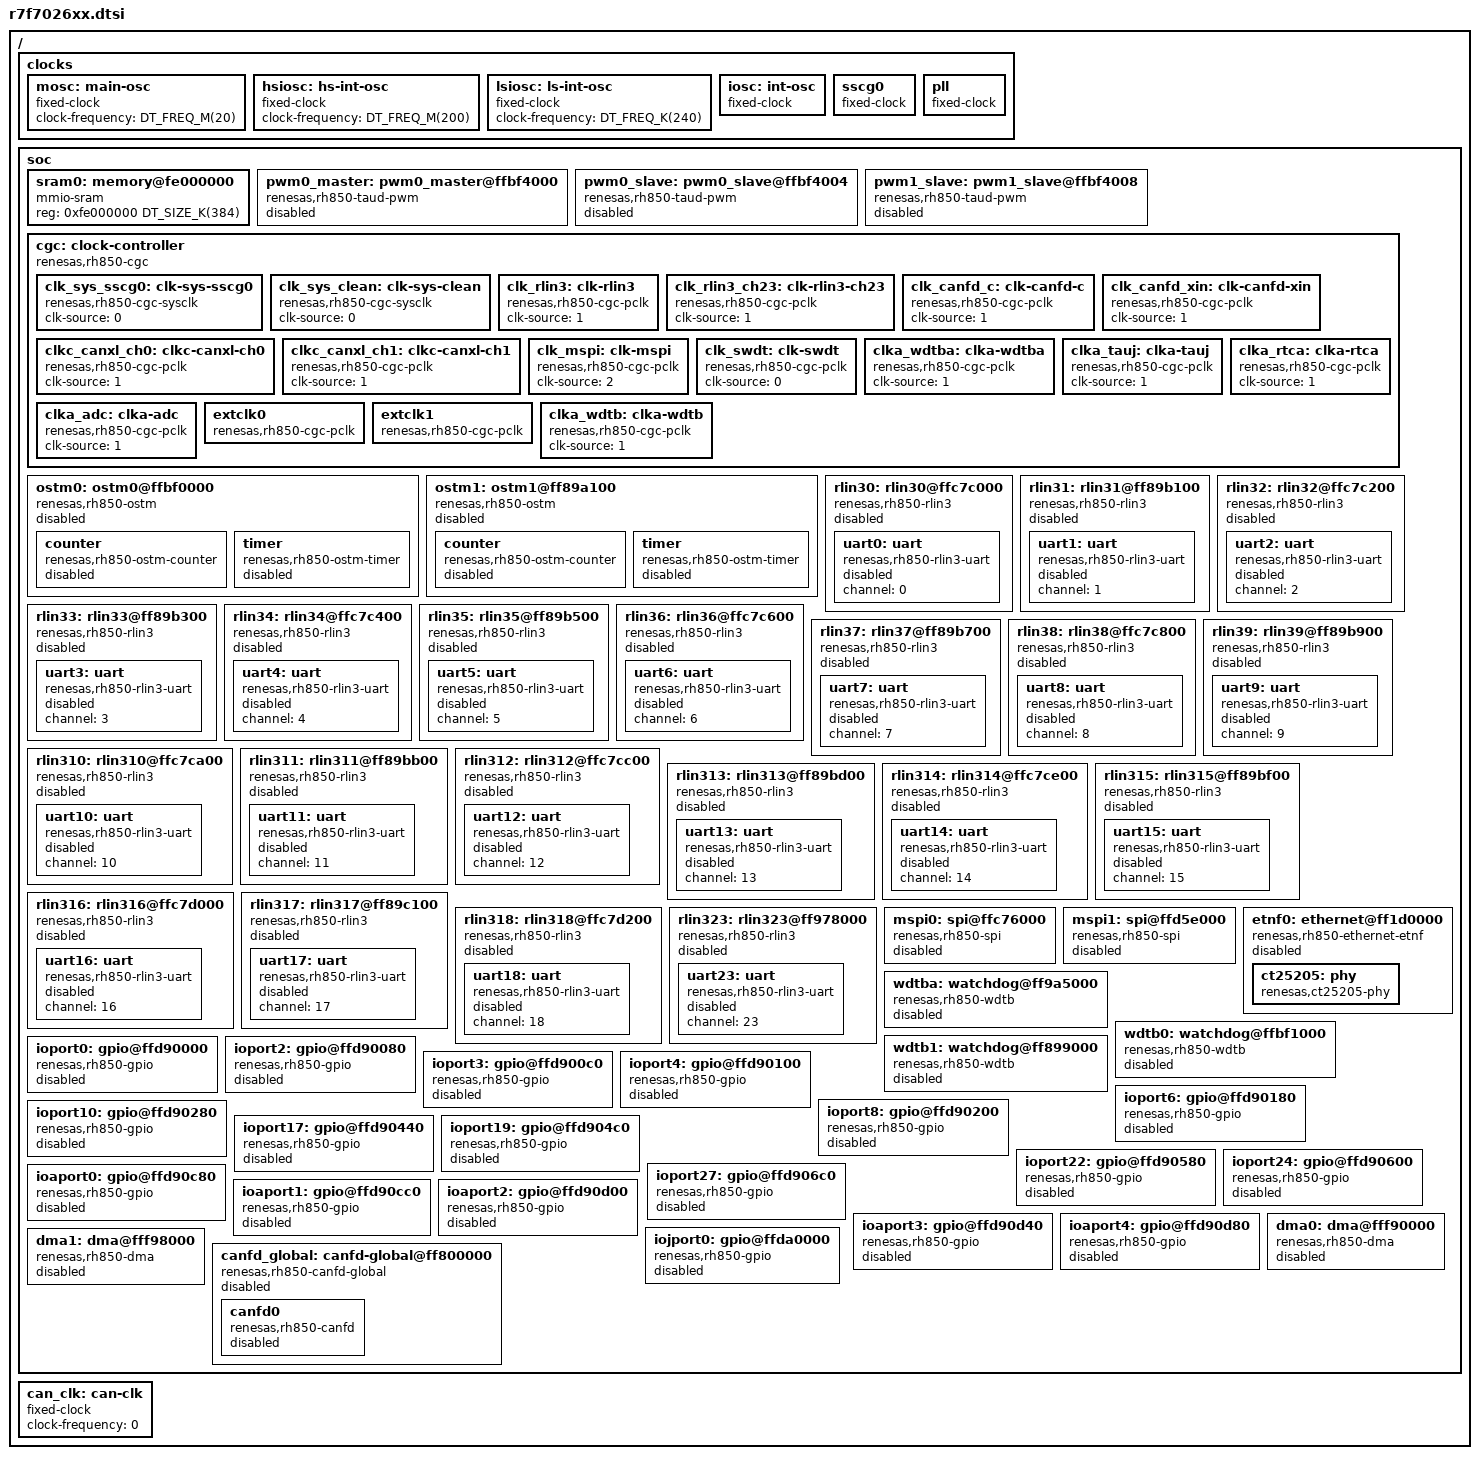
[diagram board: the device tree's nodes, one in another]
/*
 * Copyright (c) 2026 Renesas Electronics Corporation
 *
 * SPDX-License-Identifier: Apache-2.0
 */

#include <rh850/renesas/rh850u2c/u2c-g4kh-common.dtsi>
#include <zephyr/dt-bindings/clock/renesas_rh850u2c_clock.h>
#include <zephyr/dt-bindings/gpio/gpio.h>
#include <freq.h>

/ {
	clocks {
		mosc: main-osc {
			compatible = "fixed-clock";
			clock-frequency = <DT_FREQ_M(20)>;
			#clock-cells = <0>;
			status = "okay";
		};

		hsiosc: hs-int-osc {
			compatible = "fixed-clock";
			clock-frequency = <DT_FREQ_M(200)>;
			#clock-cells = <0>;
			status = "okay";
		};

		lsiosc: ls-int-osc {
			compatible = "fixed-clock";
			clock-frequency = <DT_FREQ_K(240)>;
			#clock-cells = <0>;
			status = "okay";
		};

		iosc: int-osc {
			compatible = "fixed-clock";
			clock-frequency = <DT_FREQ_M(200)>;
			clocks = <&hsiosc>;
			#clock-cells = <0>;
			status = "okay";
		};

		sscg0: sscg0 {
			compatible = "fixed-clock";
			clock-frequency = <DT_FREQ_M(800)>;
			clocks = <&mosc>;
			#clock-cells = <0>;
			status = "okay";
		};

		pll: pll {
			compatible = "fixed-clock";
			clock-frequency = <DT_FREQ_M(800)>;
			clocks = <&mosc>;
			#clock-cells = <0>;
			status = "okay";
		};
	};

	soc {
		sram0: memory@fe000000 {
			compatible = "mmio-sram";
			reg = <0xfe000000 DT_SIZE_K(384)>;
		};

		pwm0_master: pwm0_master@ffbf4000 {
			compatible = "renesas,rh850-taud-pwm";
			reg = <0xffbf4000 0x2000>;
			unit = <0>;
			channel = <0>;
			channel-type = "master";
			interrupts = <10 1>;
			interrupt-parent = <&intc2>;
			status = "disabled";
		};

		pwm0_slave: pwm0_slave@ffbf4004 {
			compatible = "renesas,rh850-taud-pwm";
			reg = <0xffbf4004 0x2000>;
			unit = <0>;
			channel = <1>;
			channel-type = "slave";
			master = <&pwm0_master>;
			interrupts = <149 1>;
			interrupt-parent = <&intc2>;
			#pwm-cells = <3>;
			status = "disabled";
		};

		pwm1_slave: pwm1_slave@ffbf4008 {
			compatible = "renesas,rh850-taud-pwm";
			reg = <0xffbf4008 0x2000>;
			unit = <0>;
			channel = <2>;
			channel-type = "slave";
			master = <&pwm0_master>;
			interrupts = <11 1>;
			interrupt-parent = <&intc2>;
			#pwm-cells = <3>;
			status = "disabled";
		};

		cgc: clock-controller {
			compatible = "renesas,rh850-cgc";
			#clock-cells = <1>;
			status = "okay";

			clk_sys_sscg0: clk-sys-sscg0 {
				compatible = "renesas,rh850-cgc-sysclk";
				clk-source = <0>;
				#clock-cells = <0>;
				status = "okay";
			};

			clk_sys_clean: clk-sys-clean {
				compatible = "renesas,rh850-cgc-sysclk";
				clk-source = <0>;
				#clock-cells = <0>;
				status = "okay";
			};

			clk_rlin3: clk-rlin3 {
				compatible = "renesas,rh850-cgc-pclk";
				clk-source = <1>;
				#clock-cells = <0>;
				status = "okay";
			};

			clk_rlin3_ch23: clk-rlin3-ch23 {
				compatible = "renesas,rh850-cgc-pclk";
				clk-source = <1>;
				#clock-cells = <0>;
				status = "okay";
			};

			clk_canfd_c: clk-canfd-c {
				compatible = "renesas,rh850-cgc-pclk";
				clk-source = <1>;
				#clock-cells = <0>;
				status = "okay";
			};

			clk_canfd_xin: clk-canfd-xin {
				compatible = "renesas,rh850-cgc-pclk";
				clk-source = <1>;
				#clock-cells = <0>;
				status = "okay";
			};

			clkc_canxl_ch0: clkc-canxl-ch0 {
				compatible = "renesas,rh850-cgc-pclk";
				clk-source = <1>;
				#clock-cells = <0>;
				status = "okay";
			};

			clkc_canxl_ch1: clkc-canxl-ch1 {
				compatible = "renesas,rh850-cgc-pclk";
				clk-source = <1>;
				#clock-cells = <0>;
				status = "okay";
			};

			clk_mspi: clk-mspi {
				compatible = "renesas,rh850-cgc-pclk";
				clk-source = <2>;
				#clock-cells = <0>;
				status = "okay";
			};

			clk_swdt: clk-swdt {
				compatible = "renesas,rh850-cgc-pclk";
				clk-source = <0>;
				#clock-cells = <0>;
				status = "okay";
			};

			clka_wdtba: clka-wdtba {
				compatible = "renesas,rh850-cgc-pclk";
				clk-source = <1>;
				#clock-cells = <0>;
				status = "okay";
			};

			clka_tauj: clka-tauj {
				compatible = "renesas,rh850-cgc-pclk";
				clk-source = <1>;
				#clock-cells = <0>;
				status = "okay";
			};

			clka_rtca: clka-rtca {
				compatible = "renesas,rh850-cgc-pclk";
				clk-source = <1>;
				#clock-cells = <0>;
				status = "okay";
			};

			clka_adc: clka-adc {
				compatible = "renesas,rh850-cgc-pclk";
				clk-source = <1>;
				#clock-cells = <0>;
				status = "okay";
			};

			extclk0: extclk0 {
				compatible = "renesas,rh850-cgc-pclk";
				clk-source = <4>;
				div = <0>;
				#clock-cells = <0>;
				status = "okay";
			};

			extclk1: extclk1 {
				compatible = "renesas,rh850-cgc-pclk";
				clk-source = <4>;
				div = <0>;
				#clock-cells = <0>;
				status = "okay";
			};

			clka_wdtb: clka-wdtb {
				compatible = "renesas,rh850-cgc-pclk";
				clk-source = <1>;
				#clock-cells = <0>;
				status = "okay";
			};
		};

		ostm0: ostm0@ffbf0000 {
			compatible = "renesas,rh850-ostm";
			reg = <0xffbf0000 0x20>;
			channel = <0>;
			interrupts = <63 1>;
			interrupt-names = "overflow";
			interrupt-parent = <&intc2>;
			clocks = <&cgc RH850_PCLK(OSTM, 0, PCLK)>;
			status = "disabled";

			counter {
				compatible = "renesas,rh850-ostm-counter";
				status = "disabled";
			};

			timer {
				compatible = "renesas,rh850-ostm-timer";
				status = "disabled";
			};
		};

		ostm1: ostm1@ff89a100 {
			compatible = "renesas,rh850-ostm";
			reg = <0xff89a100 0x20>;
			channel = <1>;
			interrupts = <484 1>;
			interrupt-names = "overflow";
			interrupt-parent = <&intc2>;
			clocks = <&cgc RH850_PCLK(OSTM, 1, PCLK)>;
			status = "disabled";

			counter {
				compatible = "renesas,rh850-ostm-counter";
				status = "disabled";
			};

			timer {
				compatible = "renesas,rh850-ostm-timer";
				status = "disabled";
			};
		};

		rlin30: rlin30@ffc7c000 {
			compatible = "renesas,rh850-rlin3";
			interrupts = <173 1>, <174 1>, <175 1>, <176 1>;
			interrupt-names = "rlin3i", "txi", "rxi", "eri";
			reg = <0xffc7c000 0x35>;
			interrupt-parent = <&intc2>;
			clocks = <&cgc RH850_PCLK(RLIN3, 0, RLIN3)>;
			status = "disabled";

			uart0: uart {
				compatible = "renesas,rh850-rlin3-uart";
				channel = <0>;
				status = "disabled";
			};
		};

		rlin31: rlin31@ff89b100 {
			compatible = "renesas,rh850-rlin3";
			interrupts = <178 1>, <179 1>, <180 1>, <181 1>;
			interrupt-names = "rlin3i", "txi", "rxi", "eri";
			reg = <0xff89b100 0x35>;
			interrupt-parent = <&intc2>;
			clocks = <&cgc RH850_PCLK(RLIN3, 1, RLIN3)>;
			status = "disabled";

			uart1: uart {
				compatible = "renesas,rh850-rlin3-uart";
				channel = <1>;
				status = "disabled";
			};
		};

		rlin32: rlin32@ffc7c200 {
			compatible = "renesas,rh850-rlin3";
			interrupts = <183 1>, <184 1>, <185 1>, <186 1>;
			interrupt-names = "rlin3i", "txi", "rxi", "eri";
			reg = <0xffc7c200 0x35>;
			interrupt-parent = <&intc2>;
			clocks = <&cgc RH850_PCLK(RLIN3, 2, RLIN3)>;
			status = "disabled";

			uart2: uart {
				compatible = "renesas,rh850-rlin3-uart";
				channel = <2>;
				status = "disabled";
			};
		};

		rlin33: rlin33@ff89b300 {
			compatible = "renesas,rh850-rlin3";
			interrupts = <188 1>, <189 1>, <190 1>, <191 1>;
			interrupt-names = "rlin3i", "txi", "rxi", "eri";
			reg = <0xff89b300 0x35>;
			interrupt-parent = <&intc2>;
			clocks = <&cgc RH850_PCLK(RLIN3, 3, RLIN3)>;
			status = "disabled";

			uart3: uart {
				compatible = "renesas,rh850-rlin3-uart";
				channel = <3>;
				status = "disabled";
			};
		};

		rlin34: rlin34@ffc7c400 {
			compatible = "renesas,rh850-rlin3";
			interrupts = <193 1>, <194 1>, <195 1>, <196 1>;
			interrupt-names = "rlin3i", "txi", "rxi", "eri";
			reg = <0xffc7c400 0x35>;
			interrupt-parent = <&intc2>;
			clocks = <&cgc RH850_PCLK(RLIN3, 4, RLIN3)>;
			status = "disabled";

			uart4: uart {
				compatible = "renesas,rh850-rlin3-uart";
				channel = <4>;
				status = "disabled";
			};
		};

		rlin35: rlin35@ff89b500 {
			compatible = "renesas,rh850-rlin3";
			interrupts = <197 1>, <198 1>, <199 1>, <200 1>;
			interrupt-names = "rlin3i", "txi", "rxi", "eri";
			reg = <0xff89b500 0x35>;
			interrupt-parent = <&intc2>;
			clocks = <&cgc RH850_PCLK(RLIN3, 5, RLIN3)>;
			status = "disabled";

			uart5: uart {
				compatible = "renesas,rh850-rlin3-uart";
				channel = <5>;
				status = "disabled";
			};
		};

		rlin36: rlin36@ffc7c600 {
			compatible = "renesas,rh850-rlin3";
			interrupts = <201 1>, <202 1>, <203 1>, <204 1>;
			interrupt-names = "rlin3i", "txi", "rxi", "eri";
			reg = <0xffc7c600 0x35>;
			interrupt-parent = <&intc2>;
			clocks = <&cgc RH850_PCLK(RLIN3, 6, RLIN3)>;
			status = "disabled";

			uart6: uart {
				compatible = "renesas,rh850-rlin3-uart";
				channel = <6>;
				status = "disabled";
			};
		};

		rlin37: rlin37@ff89b700 {
			compatible = "renesas,rh850-rlin3";
			interrupts = <394 1>, <395 1>, <396 1>, <397 1>;
			interrupt-names = "rlin3i", "txi", "rxi", "eri";
			reg = <0xff89b700 0x35>;
			interrupt-parent = <&intc2>;
			clocks = <&cgc RH850_PCLK(RLIN3, 7, RLIN3)>;
			status = "disabled";

			uart7: uart {
				compatible = "renesas,rh850-rlin3-uart";
				channel = <7>;
				status = "disabled";
			};
		};

		rlin38: rlin38@ffc7c800 {
			compatible = "renesas,rh850-rlin3";
			interrupts = <398 1>, <399 1>, <400 1>, <401 1>;
			interrupt-names = "rlin3i", "txi", "rxi", "eri";
			reg = <0xffc7c800 0x35>;
			interrupt-parent = <&intc2>;
			clocks = <&cgc RH850_PCLK(RLIN3, 8, RLIN3)>;
			status = "disabled";

			uart8: uart {
				compatible = "renesas,rh850-rlin3-uart";
				channel = <8>;
				status = "disabled";
			};
		};

		rlin39: rlin39@ff89b900 {
			compatible = "renesas,rh850-rlin3";
			interrupts = <402 1>, <403 1>, <404 1>, <405 1>;
			interrupt-names = "rlin3i", "txi", "rxi", "eri";
			reg = <0xff89b900 0x35>;
			interrupt-parent = <&intc2>;
			clocks = <&cgc RH850_PCLK(RLIN3, 9, RLIN3)>;
			status = "disabled";

			uart9: uart {
				compatible = "renesas,rh850-rlin3-uart";
				channel = <9>;
				status = "disabled";
			};
		};

		rlin310: rlin310@ffc7ca00 {
			compatible = "renesas,rh850-rlin3";
			interrupts = <406 1>, <407 1>, <408 1>, <409 1>;
			interrupt-names = "rlin3i", "txi", "rxi", "eri";
			reg = <0xffc7ca00 0x35>;
			interrupt-parent = <&intc2>;
			clocks = <&cgc RH850_PCLK(RLIN3, 10, RLIN3)>;
			status = "disabled";

			uart10: uart {
				compatible = "renesas,rh850-rlin3-uart";
				channel = <10>;
				status = "disabled";
			};
		};

		rlin311: rlin311@ff89bb00 {
			compatible = "renesas,rh850-rlin3";
			interrupts = <493 1>, <494 1>, <495 1>, <496 1>;
			interrupt-names = "rlin3i", "txi", "rxi", "eri";
			reg = <0xff89bb00 0x35>;
			interrupt-parent = <&intc2>;
			clocks = <&cgc RH850_PCLK(RLIN3, 11, RLIN3)>;
			status = "disabled";

			uart11: uart {
				compatible = "renesas,rh850-rlin3-uart";
				channel = <11>;
				status = "disabled";
			};
		};

		rlin312: rlin312@ffc7cc00 {
			compatible = "renesas,rh850-rlin3";
			interrupts = <497 1>, <498 1>, <499 1>, <500 1>;
			interrupt-names = "rlin3i", "txi", "rxi", "eri";
			reg = <0xffc7cc00 0x35>;
			interrupt-parent = <&intc2>;
			clocks = <&cgc RH850_PCLK(RLIN3, 12, RLIN3)>;
			status = "disabled";

			uart12: uart {
				compatible = "renesas,rh850-rlin3-uart";
				channel = <12>;
				status = "disabled";
			};
		};

		rlin313: rlin313@ff89bd00 {
			compatible = "renesas,rh850-rlin3";
			interrupts = <501 1>, <502 1>, <503 1>, <504 1>;
			interrupt-names = "rlin3i", "txi", "rxi", "eri";
			reg = <0xff89bd00 0x3e0f00>;
			interrupt-parent = <&intc2>;
			clocks = <&cgc RH850_PCLK(RLIN3, 13, RLIN3)>;
			status = "disabled";

			uart13: uart {
				compatible = "renesas,rh850-rlin3-uart";
				channel = <13>;
				status = "disabled";
			};
		};

		rlin314: rlin314@ffc7ce00 {
			compatible = "renesas,rh850-rlin3";
			interrupts = <505 1>, <506 1>, <507 1>, <508 1>;
			interrupt-names = "rlin3i", "txi", "rxi", "eri";
			reg = <0xffc7ce00 0x35>;
			interrupt-parent = <&intc2>;
			clocks = <&cgc RH850_PCLK(RLIN3, 14, RLIN3)>;
			status = "disabled";

			uart14: uart {
				compatible = "renesas,rh850-rlin3-uart";
				channel = <14>;
				status = "disabled";
			};
		};

		rlin315: rlin315@ff89bf00 {
			compatible = "renesas,rh850-rlin3";
			interrupts = <568 1>, <569 1>, <570 1>, <571 1>;
			interrupt-names = "rlin3i", "txi", "rxi", "eri";
			reg = <0xff89bf00 0x35>;
			interrupt-parent = <&intc2>;
			clocks = <&cgc RH850_PCLK(RLIN3, 15, RLIN3)>;
			status = "disabled";

			uart15: uart {
				compatible = "renesas,rh850-rlin3-uart";
				channel = <15>;
				status = "disabled";
			};
		};

		rlin316: rlin316@ffc7d000 {
			compatible = "renesas,rh850-rlin3";
			interrupts = <572 1>, <573 1>, <574 1>, <575 1>;
			interrupt-names = "rlin3i", "txi", "rxi", "eri";
			reg = <0xffc7d000 0x35>;
			interrupt-parent = <&intc2>;
			clocks = <&cgc RH850_PCLK(RLIN3, 16, RLIN3)>;
			status = "disabled";

			uart16: uart {
				compatible = "renesas,rh850-rlin3-uart";
				channel = <16>;
				status = "disabled";
			};
		};

		rlin317: rlin317@ff89c100 {
			compatible = "renesas,rh850-rlin3";
			interrupts = <576 1>, <577 1>, <578 1>, <579 1>;
			interrupt-names = "rlin3i", "txi", "rxi", "eri";
			reg = <0xff89c100 0x35>;
			interrupt-parent = <&intc2>;
			clocks = <&cgc RH850_PCLK(RLIN3, 17, RLIN3)>;
			status = "disabled";

			uart17: uart {
				compatible = "renesas,rh850-rlin3-uart";
				channel = <17>;
				status = "disabled";
			};
		};

		rlin318: rlin318@ffc7d200 {
			compatible = "renesas,rh850-rlin3";
			interrupts = <580 1>, <581 1>, <582 1>, <583 1>;
			interrupt-names = "rlin3i", "txi", "rxi", "eri";
			reg = <0xffc7d200 0x35>;
			interrupt-parent = <&intc2>;
			clocks = <&cgc RH850_PCLK(RLIN3, 18, RLIN3)>;
			status = "disabled";

			uart18: uart {
				compatible = "renesas,rh850-rlin3-uart";
				channel = <18>;
				status = "disabled";
			};
		};

		rlin323: rlin323@ff978000 {
			compatible = "renesas,rh850-rlin3";
			interrupts = <205 1>, <206 1>, <207 1>, <208 1>;
			interrupt-names = "rlin3i", "txi", "rxi", "eri";
			reg = <0xff978000 0x35>;
			interrupt-parent = <&intc2>;
			clocks = <&cgc RH850_PCLK(RLIN3, 23, CH23_RLIN3)>;
			status = "disabled";

			uart23: uart {
				compatible = "renesas,rh850-rlin3-uart";
				channel = <23>;
				status = "disabled";
			};
		};

		mspi0: spi@ffc76000 {
			compatible = "renesas,rh850-spi";
			interrupts = <76 1>, <79 1>, <90 1>, <91 1>;
			interrupt-names = "txi", "rxi", "tei", "eri";
			reg = <0xffc76000 0x680>;
			interrupt-parent = <&intc2>;
			#address-cells = <1>;
			#size-cells = <0>;
			channel = <0>;
			status = "disabled";
		};

		mspi1: spi@ffd5e000 {
			compatible = "renesas,rh850-spi";
			interrupts = <82 1>, <85 1>, <90 1>, <91 1>;
			interrupt-names = "txi", "rxi", "tei", "eri";
			reg = <0xffd5e000 0x680>;
			interrupt-parent = <&intc2>;
			#address-cells = <1>;
			#size-cells = <0>;
			channel = <0>;
			status = "disabled";
		};

		/* ETNF0 MAC node */
		etnf0: ethernet@ff1d0000 {
			compatible = "renesas,rh850-ethernet-etnf";
			reg = <0xff1d0000 0x77c>;
			interrupts = <536 0>;
			interrupt-parent = <&intc2>;
			phy-connection-type = "internal";
			mdio-interface = "shared";
			pma-filtered;
			status = "disabled";

			ct25205: phy {
				compatible = "renesas,ct25205-phy";
				phy-lsi-addr = <31>;
				plca-enable;
				plca-node-id = <0>;
				plca-node-count = <8>;
				plca-burst-count = <0>;
				plca-burst-timer = <128>;
				plca-to-timer = <32>;
				status = "okay";
			};
		};

		wdtba: watchdog@ff9a5000 {
			unit = <0>;
			compatible = "renesas,rh850-wdtb";
			interrupts = <306 0>;
			window-open-mode = "select-by-window-start";
			error-mode = "nmi-mode";
			clock-freq = <256>;
			reg = <0xff9a5000 0x14>;
			interrupt-parent = <&intc2>;
			status = "disabled";
		};

		wdtb0: watchdog@ffbf1000 {
			unit = <1>;
			compatible = "renesas,rh850-wdtb";
			interrupts = <22 0>;
			window-open-mode = "select-by-window-start";
			error-mode = "nmi-mode";
			clock-freq = <312500>;
			reg = <0xffbf1000 0x14>;
			interrupt-parent = <&intc2>;
			status = "disabled";
		};

		wdtb1: watchdog@ff899000 {
			unit = <2>;
			compatible = "renesas,rh850-wdtb";
			interrupts = <22 0>;
			window-open-mode = "select-by-window-start";
			error-mode = "nmi-mode";
			clock-freq = <312500>;
			reg = <0xff899000 0x14>;
			interrupt-parent = <&intc2>;
			status = "disabled";
		};

		ioport0: gpio@ffd90000 {
			compatible = "renesas,rh850-gpio";
			reg = <0xffd90000 0x40>;
			port = <0>;
			protected-write-mask = <0>;
			port-type = "port";
			#gpio-cells = <2>;
			gpio-controller;
			status = "disabled";
		};

		ioport2: gpio@ffd90080 {
			compatible = "renesas,rh850-gpio";
			reg = <0xffd90080 0x40>;
			port = <2>;
			protected-write-mask = <2>;
			port-type = "port";
			#gpio-cells = <2>;
			gpio-controller;
			status = "disabled";
		};

		ioport3: gpio@ffd900c0 {
			compatible = "renesas,rh850-gpio";
			reg = <0xffd900c0 0x40>;
			port = <3>;
			protected-write-mask = <3>;
			port-type = "port";
			#gpio-cells = <2>;
			gpio-controller;
			status = "disabled";
		};

		ioport4: gpio@ffd90100 {
			compatible = "renesas,rh850-gpio";
			reg = <0xffd90100 0x40>;
			port = <4>;
			protected-write-mask = <4>;
			port-type = "port";
			#gpio-cells = <2>;
			gpio-controller;
			status = "disabled";
		};

		ioport6: gpio@ffd90180 {
			compatible = "renesas,rh850-gpio";
			reg = <0xffd90180 0x40>;
			port = <6>;
			protected-write-mask = <6>;
			port-type = "port";
			#gpio-cells = <2>;
			gpio-controller;
			status = "disabled";
		};

		ioport8: gpio@ffd90200 {
			compatible = "renesas,rh850-gpio";
			reg = <0xffd90200 0x40>;
			port = <8>;
			protected-write-mask = <7>;
			port-type = "port";
			#gpio-cells = <2>;
			gpio-controller;
			status = "disabled";
		};

		ioport10: gpio@ffd90280 {
			compatible = "renesas,rh850-gpio";
			reg = <0xffd90280 0x40>;
			port = <10>;
			protected-write-mask = <8>;
			port-type = "port";
			#gpio-cells = <2>;
			gpio-controller;
			status = "disabled";
		};

		ioport17: gpio@ffd90440 {
			compatible = "renesas,rh850-gpio";
			reg = <0xffd90440 0x40>;
			port = <17>;
			protected-write-mask = <10>;
			port-type = "port";
			#gpio-cells = <2>;
			gpio-controller;
			status = "disabled";
		};

		ioport19: gpio@ffd904c0 {
			compatible = "renesas,rh850-gpio";
			reg = <0xffd904c0 0x40>;
			port = <19>;
			protected-write-mask = <11>;
			port-type = "port";
			#gpio-cells = <2>;
			gpio-controller;
			status = "disabled";
		};

		ioport22: gpio@ffd90580 {
			compatible = "renesas,rh850-gpio";
			reg = <0xffd90580 0x40>;
			port = <22>;
			protected-write-mask = <14>;
			port-type = "port";
			#gpio-cells = <2>;
			gpio-controller;
			status = "disabled";
		};

		ioport24: gpio@ffd90600 {
			compatible = "renesas,rh850-gpio";
			reg = <0xffd90600 0x40>;
			port = <24>;
			protected-write-mask = <15>;
			port-type = "port";
			#gpio-cells = <2>;
			gpio-controller;
			status = "disabled";
		};

		ioport27: gpio@ffd906c0 {
			compatible = "renesas,rh850-gpio";
			reg = <0xffd906c0 0x40>;
			port = <27>;
			protected-write-mask = <16>;
			port-type = "port";
			#gpio-cells = <2>;
			gpio-controller;
			status = "disabled";
		};

		ioaport0: gpio@ffd90c80 {
			compatible = "renesas,rh850-gpio";
			reg = <0xffd90c80 0x40>;
			port = <0>;
			protected-write-mask = <20>;
			port-type = "aport";
			#gpio-cells = <2>;
			gpio-controller;
			status = "disabled";
		};

		ioaport1: gpio@ffd90cc0 {
			compatible = "renesas,rh850-gpio";
			reg = <0xffd90cc0 0x40>;
			port = <1>;
			protected-write-mask = <21>;
			port-type = "aport";
			#gpio-cells = <2>;
			gpio-controller;
			status = "disabled";
		};

		ioaport2: gpio@ffd90d00 {
			compatible = "renesas,rh850-gpio";
			reg = <0xffd90d00 0x40>;
			port = <2>;
			protected-write-mask = <22>;
			port-type = "aport";
			#gpio-cells = <2>;
			gpio-controller;
			status = "disabled";
		};

		ioaport3: gpio@ffd90d40 {
			compatible = "renesas,rh850-gpio";
			reg = <0xffd90d40 0x40>;
			port = <3>;
			protected-write-mask = <23>;
			port-type = "aport";
			#gpio-cells = <2>;
			gpio-controller;
			status = "disabled";
		};

		ioaport4: gpio@ffd90d80 {
			compatible = "renesas,rh850-gpio";
			reg = <0xffd90d80 0x40>;
			port = <4>;
			protected-write-mask = <24>;
			port-type = "aport";
			#gpio-cells = <2>;
			gpio-controller;
			status = "disabled";
		};

		iojport0: gpio@ffda0000 {
			compatible = "renesas,rh850-gpio";
			reg = <0xffda0000 0x40>;
			port = <0>;
			protected-write-mask = <255>;
			port-type = "jport";
			#gpio-cells = <2>;
			gpio-controller;
			status = "disabled";
		};

		dma0: dma@fff90000 {
			compatible = "renesas,rh850-dma";
			reg = <0xfff90000 0x5000>, <0xfff95000 0x020>;
			reg-names = "reg_main", "ext";
			interrupts = <41 1>, <42 1>, <43 1>, <44 1>,
				     <45 1>, <46 1>, <47 1>, <48 1>,
				     <49 1>, <50 1>, <51 1>, <52 1>,
				     <53 1>, <54 1>, <55 1>, <56 1>;
			interrupt-names = "ch0", "ch1", "ch2", "ch3",
					  "ch4", "ch5", "ch6", "ch7",
					  "ch8", "ch9", "ch10", "ch11",
					  "ch12", "ch13", "ch14", "ch15";
			interrupt-parent = <&intc2>;
			dma-unit = <0>;
			dma-channels = <16>;
			#dma-cells = <2>;
			status = "disabled";
		};

		dma1: dma@fff98000 {
			compatible = "renesas,rh850-dma";
			reg = <0xfff98000 0x5000>, <0xfff9d000 0x020>;
			reg-names = "reg_main", "ext";
			interrupts = <320 1>, <321 1>, <322 1>, <323 1>,
				     <324 1>, <325 1>, <326 1>, <327 1>,
				     <328 1>, <329 1>, <330 1>, <331 1>,
				     <332 1>, <333 1>, <334 1>, <335 1>;
			interrupt-names = "ch0", "ch1", "ch2", "ch3",
					  "ch4", "ch5", "ch6", "ch7",
					  "ch8", "ch9", "ch10", "ch11",
					  "ch12", "ch13", "ch14", "ch15";
			interrupt-parent = <&intc2>;
			dma-unit = <1>;
			dma-channels = <16>;
			#dma-cells = <2>;
			status = "disabled";
		};

		canfd_global: canfd-global@ff800000 {
			compatible = "renesas,rh850-canfd-global";
			reg = <0xff800000 DT_SIZE_K(128)>;
			interrupts = <104 1>, <105 1>;
			interrupt-names = "g_err", "g_recc";
			interrupt-parent = <&intc2>;
			status = "disabled";

			canfd0: canfd0 {
				compatible = "renesas,rh850-canfd";
				channel = <0>;
				interrupts = <107 1>, <106 1>, <108 1>;
				interrupt-names = "rxi", "eri", "txi";
				interrupt-parent = <&intc2>;
				clock-frequency = <80000000>;
				status = "disabled";
			};
		};
	};

	/* External CAN clock - to be overridden by boards that provide it */
	can_clk: can-clk {
		compatible = "fixed-clock";
		clock-frequency = <0>;
		#clock-cells = <0>;
	};
};
